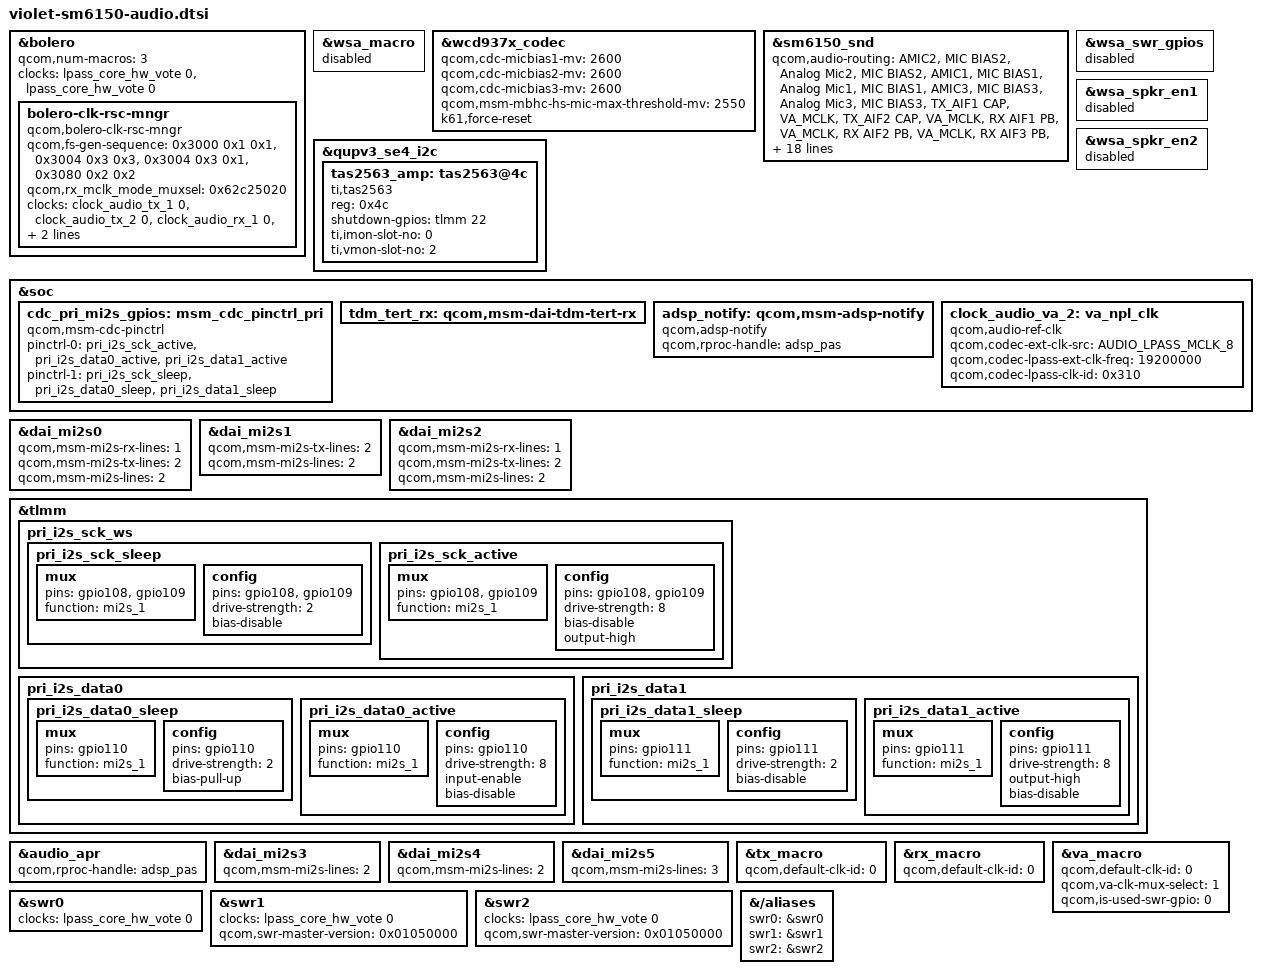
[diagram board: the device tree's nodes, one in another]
/*
 * Copyright (C) 2020 The LineageOS Project
 *
 * this file is for attribution only of violet
 * And public attribution of Xiaomi platforms (like F7B and so)
 */

&bolero {
    qcom,num-macros = <3>;
    /* the VA link uses va_macro_tx1: the VA macro must export its DAIs */
    /delete-property/ qcom,va-without-decimation;
};

&wsa_macro {
    status = "disabled";
};

&wcd937x_codec {
    qcom,cdc-micbias1-mv = <2600>;
    qcom,cdc-micbias2-mv = <2600>;
    qcom,cdc-micbias3-mv = <2600>;
    qcom,msm-mbhc-hs-mic-max-threshold-mv = <2550>;
};

&sm6150_snd {
    qcom,audio-routing =
        "AMIC2", "MIC BIAS2",
        "Analog Mic2", "MIC BIAS2",
        "AMIC1", "MIC BIAS1",
        "Analog Mic1", "MIC BIAS1",
        "AMIC3", "MIC BIAS3",
        "Analog Mic3", "MIC BIAS3",
        "TX_AIF1 CAP", "VA_MCLK",
        "TX_AIF2 CAP", "VA_MCLK",
        "RX AIF1 PB", "VA_MCLK",
        "RX AIF2 PB", "VA_MCLK",
        "RX AIF3 PB", "VA_MCLK",
        "RX AIF4 PB", "VA_MCLK",
        "HPHL_OUT", "VA_MCLK",
        "HPHR_OUT", "VA_MCLK",
        "AUX_OUT", "VA_MCLK",
        "IN1_HPHL", "HPHL_OUT",
        "IN2_HPHR", "HPHR_OUT",
        "IN3_AUX", "AUX_OUT",
        "TX SWR_ADC0", "ADC1_OUTPUT",
        "TX SWR_ADC2", "ADC2_OUTPUT",
        "RX_TX DEC0_INP", "TX DEC0 MUX",
        "RX_TX DEC1_INP", "TX DEC1 MUX",
        "RX_TX DEC2_INP", "TX DEC2 MUX",
        "RX_TX DEC3_INP", "TX DEC3 MUX";
    qcom,pri-mi2s-gpios = <&cdc_pri_mi2s_gpios>;
    qcom,wsa-max-devs = <0>;
    /delete-property/ qcom,wsa-devs;
};

&qupv3_se4_i2c {
    status = "ok";
    tas2563_amp: tas2563@4c {
        #sound-dai-cells = <0>;
        compatible = "ti,tas2563";
        reg = <0x4c>;
        shutdown-gpios = <&tlmm 22 0>;
        ti,imon-slot-no = <0>;
        ti,vmon-slot-no = <2>;
        status = "ok";
    };
};

&wsa_swr_gpios {
    status = "disabled";
};

&wsa_spkr_en1 {
    status = "disabled";
};

&wsa_spkr_en2 {
    status = "disabled";
};

&soc {
    cdc_pri_mi2s_gpios: msm_cdc_pinctrl_pri {
        compatible = "qcom,msm-cdc-pinctrl";
        pinctrl-names = "aud_active", "aud_sleep";
        pinctrl-0 = <&pri_i2s_sck_active &pri_i2s_data0_active
                 &pri_i2s_data1_active>;
        pinctrl-1 = <&pri_i2s_sck_sleep &pri_i2s_data0_sleep
                 &pri_i2s_data1_sleep>;
    };

    tdm_tert_rx: qcom,msm-dai-tdm-tert-rx {
        /delete-property/ pinctrl-names;
        /delete-property/ pinctrl-0;
        /delete-property/ pinctrl-1;
    };
};

&dai_mi2s0 {
    qcom,msm-mi2s-rx-lines = <1>;
    qcom,msm-mi2s-tx-lines = <2>;
};

&dai_mi2s1 {
    qcom,msm-mi2s-tx-lines = <2>;
};

&dai_mi2s2 {
    qcom,msm-mi2s-rx-lines = <1>;
    qcom,msm-mi2s-tx-lines = <2>;    
};

/* primary MI2S for the TAS2563 speaker amp (replaces the tertiary MI2S pins) */
&tlmm {
    /delete-node/ ter_i2s_sck_ws;

    pri_i2s_sck_ws {
        pri_i2s_sck_sleep: pri_i2s_sck_sleep {
            mux {
                pins = "gpio108", "gpio109";
                function = "mi2s_1";
            };

            config {
                pins = "gpio108", "gpio109";
                drive-strength = <2>;
                bias-disable;
            };
        };

        pri_i2s_sck_active: pri_i2s_sck_active {
            mux {
                pins = "gpio108", "gpio109";
                function = "mi2s_1";
            };

            config {
                pins = "gpio108", "gpio109";
                drive-strength = <8>;
                bias-disable;
                output-high;
            };
        };
    };
    
    /delete-node/ ter_i2s_data0;

    pri_i2s_data0 {
        pri_i2s_data0_sleep: pri_i2s_data0_sleep {
            mux {    
                pins = "gpio110";
                function = "mi2s_1";
            };

            config {
                pins = "gpio110";
                drive-strength = <2>;
                bias-pull-up;
            };
        };
            
        pri_i2s_data0_active: pri_i2s_data0_active {
            mux {
                pins = "gpio110";
                function = "mi2s_1";
            };

            config {
                pins = "gpio110";
                drive-strength = <8>;
                input-enable;
                bias-disable;
            };
        };
    };
        
    /delete-node/ ter_i2s_data1;

    pri_i2s_data1 {
        pri_i2s_data1_sleep: pri_i2s_data1_sleep {
            mux {
                pins = "gpio111";
                function = "mi2s_1";
            };

            config {
                pins = "gpio111";
                drive-strength = <2>;
                bias-disable;
            };
        };

        pri_i2s_data1_active: pri_i2s_data1_active {
            mux {
                pins = "gpio111";
                function = "mi2s_1";
            };

            config {
                pins = "gpio111";
                drive-strength = <8>;
                output-high;
                bias-disable;
            };
        };
    };
};

/* the APR driver takes the ADSP remoteproc from here (the 5.4 PIL lookup is gone) */
&audio_apr {
	qcom,rproc-handle = <&adsp_pas>;
};

/*
 * The 6.1 techpack reads one qcom,msm-mi2s-lines per MI2S interface (applied to
 * the capture direction for these nodes) instead of the 4.14 rx/tx pair.
 */
&dai_mi2s0 { qcom,msm-mi2s-lines = <2>; };
&dai_mi2s1 { qcom,msm-mi2s-lines = <2>; };
&dai_mi2s2 { qcom,msm-mi2s-lines = <2>; };
&dai_mi2s3 { qcom,msm-mi2s-lines = <2>; };
&dai_mi2s4 { qcom,msm-mi2s-lines = <2>; };
&dai_mi2s5 { qcom,msm-mi2s-lines = <3>; };

/* the audio notifier takes the ADSP rproc from this node */
&soc {
	adsp_notify: qcom,msm-adsp-notify {
		status = "ok";
		compatible = "qcom,adsp-notify";
		qcom,rproc-handle = <&adsp_pas>;
	};
};

/*
 * The 6.1 bolero/swr drivers ask for a LPASS audio hw vote clock, but the sm6150
 * ADSP firmware only knows the core hw vote (the AFE answers ADSP_EUNSUPPORTED
 * to the audio one) and audio-ref-clk cannot register the same source twice:
 * hand them the core vote clock under that name.
 */
&bolero {
	clock-names = "lpass_core_hw_vote", "lpass_audio_hw_vote";
	clocks = <&lpass_core_hw_vote 0>, <&lpass_core_hw_vote 0>;
};

/*
 * 6.1 bolero (bengal-style bindings): a clock resource manager child, a default
 * clock id per macro, and the audio hw vote clock on the soundwire masters.
 * Clock ids: TX_CORE_CLK 0, RX_CORE_CLK 1, VA_CORE_CLK 3.
 */
&soc {
	clock_audio_va_2: va_npl_clk {
		compatible = "qcom,audio-ref-clk";
		qcom,codec-ext-clk-src = <AUDIO_LPASS_MCLK_8>;
		qcom,codec-lpass-ext-clk-freq = <19200000>;
		qcom,codec-lpass-clk-id = <0x310>;
		#clock-cells = <1>;
	};
};

&bolero {
	bolero-clk-rsc-mngr {
		compatible = "qcom,bolero-clk-rsc-mngr";
		qcom,fs-gen-sequence = <0x3000 0x1 0x1>, <0x3004 0x3 0x3>,
					<0x3004 0x3 0x1>, <0x3080 0x2 0x2>;
		qcom,rx_mclk_mode_muxsel = <0x62c25020>;
		clock-names = "tx_core_clk", "tx_npl_clk", "rx_core_clk",
			"rx_npl_clk", "va_core_clk", "va_npl_clk";
		clocks = <&clock_audio_tx_1 0>, <&clock_audio_tx_2 0>,
			<&clock_audio_rx_1 0>, <&clock_audio_rx_2 0>,
			<&clock_audio_va 0>, <&clock_audio_va_2 0>;
	};
};

&tx_macro {
	qcom,default-clk-id = <0>;
};

&rx_macro {
	qcom,default-clk-id = <0>;
};

&va_macro {
	qcom,default-clk-id = <0>;
	qcom,va-clk-mux-select = <1>;
	qcom,is-used-swr-gpio = <0>;
};

&swr0 {
	clock-names = "lpass_audio_hw_vote";
	clocks = <&lpass_core_hw_vote 0>;
};

&swr1 {
	clock-names = "lpass_audio_hw_vote";
	clocks = <&lpass_core_hw_vote 0>;
};

&swr2 {
	clock-names = "lpass_audio_hw_vote";
	clocks = <&lpass_core_hw_vote 0>;
};

/* swr_register_master takes its bus number from these aliases */
&{/aliases} {
	swr0 = &swr0;
	swr1 = &swr1;
	swr2 = &swr2;
};

/* the sm6150 LPASS soundwire is v1.5 (read back from the HW: 0x1050000) */
&swr1 {
	qcom,swr-master-version = <0x01050000>;
};

&swr2 {
	qcom,swr-master-version = <0x01050000>;
};

/* the 4.14 kernel leaves the codec reset high and the chip enumerated: pulse it */
&wcd937x_codec {
	k61,force-reset;
};

/*
 * The 6.1 bengal machine driver builds its DAI link list from these: add the
 * bolero RX/TX and VA CDC-DMA links, and drop the WCN BT/FM links (they name a
 * slimbus BT codec that does not exist here, which would keep the card deferred).
 */
&sm6150_snd {
	qcom,rxtx-bolero-codec = <1>;
	qcom,va-bolero-codec = <1>;
	qcom,wcn-btfm = <0>;
	/* no BT/voice PCM on violet; the 6.1 auxpcm DAI driver does not bind our DT nodes */
	qcom,auxpcm-audio-intf = <0>;
	/* 6.1 matches link component names by device name: map them to the nodes */
	asoc-codec = <&stub_codec>, <&bolero>, <&wcd937x_codec>, <&tas2563_amp>;
	asoc-codec-names = "msm-stub-codec.1", "bolero_codec", "wcd937x_codec",
			   "tas2563";
};
